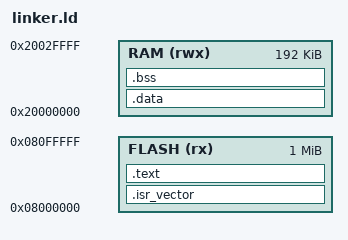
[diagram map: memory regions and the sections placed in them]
/* STM32F407VG memory map */
MEMORY
{
  FLASH (rx)  : ORIGIN = 0x08000000, LENGTH = 1024K
  RAM   (rwx) : ORIGIN = 0x20000000, LENGTH = 192K
}

/* Entry */
ENTRY(Reset_Handler)

/* Stack at the top of RAM */
_estack = ORIGIN(RAM) + LENGTH(RAM);

/* Sections */
SECTIONS
{
  .isr_vector :
  {
    KEEP(*(.isr_vector))
  } > FLASH

  .text :
  {
    *(.text*)
    *(.rodata*)
    _etext = .;
  } > FLASH

  /* Load address for .data */
  _sidata = LOADADDR(.data);

  .data : AT (ADDR(.text) + SIZEOF(.text))
  {
    _sdata = .;
    *(.data*)
    _edata = .;
  } > RAM

  .bss :
  {
    _sbss = .;
    *(.bss*)
    *(COMMON)
    _ebss = .;
  } > RAM
}


